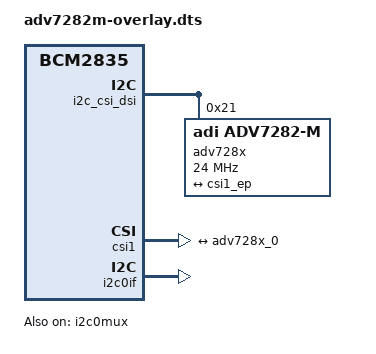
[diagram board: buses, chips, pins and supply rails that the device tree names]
// SPDX-License-Identifier: GPL-2.0-only
// Definitions for Analog Devices ADV7282-M video to CSI2 bridge on VC I2C bus
/dts-v1/;
/plugin/;

/{
	compatible = "brcm,bcm2835";

	fragment@0 {
		target = <&i2c_csi_dsi>;
		__overlay__ {
			#address-cells = <1>;
			#size-cells = <0>;
			status = "okay";

			adv728x: adv728x@21 {
				compatible = "adi,adv7282-m";
				reg = <0x21>;
				status = "okay";
				clock-frequency = <24000000>;
				port {
					adv728x_0: endpoint {
						remote-endpoint = <&csi1_ep>;
						clock-lanes = <0>;
						data-lanes = <1>;
						link-frequencies =
							/bits/ 64 <297000000>;

						mclk-frequency = <12000000>;
					};
				};
			};
		};
	};
	fragment@1 {
		target = <&csi1>;
		__overlay__ {
			status = "okay";

			port {
				csi1_ep: endpoint {
					remote-endpoint = <&adv728x_0>;
					data-lanes = <1>;
				};
			};
		};
	};
	fragment@2 {
		target = <&i2c0if>;
		__overlay__ {
			status = "okay";
		};
	};

	fragment@3 {
		target = <&i2c0mux>;
		__overlay__ {
			status = "okay";
		};
	};

	fragment@4 {
		target = <&csi1>;
		__overlay__ {
			compatible = "brcm,bcm2835-unicam-legacy";
		};
	};

	__overrides__ {
		addr = <&adv728x>,"reg:0";
		media-controller = <0>,"!4";
	};
};
